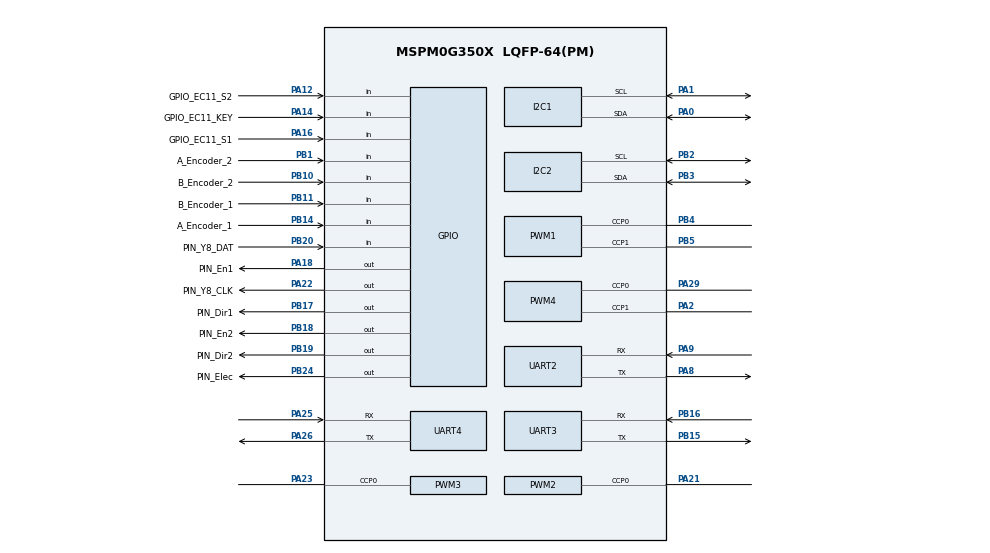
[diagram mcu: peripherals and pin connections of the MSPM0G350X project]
/**
 * @cliArgs --device "MSPM0G350X" --part "Default" --package "LQFP-64(PM)" --product "mspm0_sdk@2.09.00.00"
 * @versions {"tool":"1.26.0+4407"}
 */

/**
 * Import the modules used in this configuration.
 */
const GPIO   = scripting.addModule("/ti/driverlib/GPIO", {}, false);
const GPIO1  = GPIO.addInstance();
const GPIO2  = GPIO.addInstance();
const GPIO3  = GPIO.addInstance();
const GPIO4  = GPIO.addInstance();
const GPIO5  = GPIO.addInstance();
const GPIO6  = GPIO.addInstance();
const GPIO7  = GPIO.addInstance();
const GPIO8  = GPIO.addInstance();
const GPIO9  = GPIO.addInstance();
const GPIO10 = GPIO.addInstance();
const GPIO11 = GPIO.addInstance();
const GPIO12 = GPIO.addInstance();
const GPIO13 = GPIO.addInstance();
const GPIO14 = GPIO.addInstance();
const I2C    = scripting.addModule("/ti/driverlib/I2C", {}, false);
const I2C1   = I2C.addInstance();
const I2C2   = I2C.addInstance();
const PWM    = scripting.addModule("/ti/driverlib/PWM", {}, false);
const PWM1   = PWM.addInstance();
const PWM2   = PWM.addInstance();
const PWM3   = PWM.addInstance();
const PWM4   = PWM.addInstance();
const SYSCTL = scripting.addModule("/ti/driverlib/SYSCTL");
const TIMER  = scripting.addModule("/ti/driverlib/TIMER", {}, false);
const TIMER1 = TIMER.addInstance();
const TIMER2 = TIMER.addInstance();
const TIMER3 = TIMER.addInstance();
const UART   = scripting.addModule("/ti/driverlib/UART", {}, false);
const UART1  = UART.addInstance();
const UART2  = UART.addInstance();
const UART3  = UART.addInstance();
const UART4  = UART.addInstance();

/**
 * Write custom configuration values to the imported modules.
 */
GPIO1.$name                          = "GPIO_LED";
GPIO1.associatedPins.create(2);
GPIO1.associatedPins[0].$name        = "LED_PIN_0";
GPIO1.associatedPins[0].assignedPort = "PORTB";
GPIO1.associatedPins[0].assignedPin  = "22";
GPIO1.associatedPins[1].$name        = "LED_Time";
GPIO1.associatedPins[1].assignedPort = "PORTB";
GPIO1.associatedPins[1].assignedPin  = "9";

const Board = scripting.addModule("/ti/driverlib/Board", {}, false);

GPIO2.$name                              = "GPIO_KEY";
GPIO2.associatedPins.create(3);
GPIO2.associatedPins[0].direction        = "INPUT";
GPIO2.associatedPins[0].internalResistor = "PULL_UP";
GPIO2.associatedPins[0].assignedPort     = "PORTB";
GPIO2.associatedPins[0].assignedPin      = "21";
GPIO2.associatedPins[0].$name            = "KEY_0";
GPIO2.associatedPins[1].$name            = "KEY_1";
GPIO2.associatedPins[1].direction        = "INPUT";
GPIO2.associatedPins[1].assignedPort     = "PORTA";
GPIO2.associatedPins[1].assignedPin      = "15";
GPIO2.associatedPins[1].internalResistor = "PULL_UP";
GPIO2.associatedPins[2].$name            = "KEY_2";
GPIO2.associatedPins[2].assignedPort     = "PORTA";
GPIO2.associatedPins[2].assignedPin      = "17";
GPIO2.associatedPins[2].direction        = "INPUT";
GPIO2.associatedPins[2].internalResistor = "PULL_UP";

GPIO3.$name                          = "GPIO_OLED";
GPIO3.associatedPins.create(2);
GPIO3.associatedPins[0].$name        = "OLED_SCL";
GPIO3.associatedPins[0].initialValue = "SET";
GPIO3.associatedPins[0].assignedPort = "PORTA";
GPIO3.associatedPins[0].assignedPin  = "31";
GPIO3.associatedPins[1].$name        = "OLED_SDA";
GPIO3.associatedPins[1].initialValue = "SET";
GPIO3.associatedPins[1].assignedPort = "PORTA";
GPIO3.associatedPins[1].assignedPin  = "28";

GPIO4.$name                               = "GPIO_ENCODER_A";
GPIO4.associatedPins.create(2);
GPIO4.associatedPins[0].$name             = "A_Encoder_1";
GPIO4.associatedPins[0].direction         = "INPUT";
GPIO4.associatedPins[0].interruptEn       = true;
GPIO4.associatedPins[0].interruptPriority = "0";
GPIO4.associatedPins[0].polarity          = "RISE_FALL";
GPIO4.associatedPins[0].pin.$assign       = "PB14";
GPIO4.associatedPins[1].$name             = "A_Encoder_2";
GPIO4.associatedPins[1].direction         = "INPUT";
GPIO4.associatedPins[1].polarity          = "RISE_FALL";
GPIO4.associatedPins[1].pin.$assign       = "PB1";

GPIO5.$name                               = "GPIO_ENCODER_B";
GPIO5.associatedPins.create(2);
GPIO5.associatedPins[0].direction         = "INPUT";
GPIO5.associatedPins[0].interruptEn       = true;
GPIO5.associatedPins[0].polarity          = "RISE_FALL";
GPIO5.associatedPins[0].$name             = "B_Encoder_1";
GPIO5.associatedPins[0].interruptPriority = "0";
GPIO5.associatedPins[0].pin.$assign       = "PB11";
GPIO5.associatedPins[1].direction         = "INPUT";
GPIO5.associatedPins[1].polarity          = "RISE_FALL";
GPIO5.associatedPins[1].$name             = "B_Encoder_2";
GPIO5.associatedPins[1].pin.$assign       = "PB10";

GPIO6.$name                          = "GPIO_MOTOR_IN2";
GPIO6.associatedPins.create(2);
GPIO6.associatedPins[0].$name        = "AIN2";
GPIO6.associatedPins[0].assignedPort = "PORTB";
GPIO6.associatedPins[0].assignedPin  = "12";
GPIO6.associatedPins[1].$name        = "BIN2";
GPIO6.associatedPins[1].assignedPort = "PORTB";
GPIO6.associatedPins[1].assignedPin  = "13";

GPIO7.$name                          = "GPIO_RGB";
GPIO7.associatedPins.create(3);
GPIO7.associatedPins[0].$name        = "LED_R";
GPIO7.associatedPins[0].assignedPort = "PORTB";
GPIO7.associatedPins[0].assignedPin  = "6";
GPIO7.associatedPins[1].$name        = "LED_G";
GPIO7.associatedPins[1].assignedPort = "PORTB";
GPIO7.associatedPins[1].assignedPin  = "7";
GPIO7.associatedPins[2].$name        = "LED_B";
GPIO7.associatedPins[2].assignedPin  = "8";
GPIO7.associatedPins[2].assignedPort = "PORTB";

GPIO8.$name                              = "GPIO_TCRT";
GPIO8.associatedPins[0].$name            = "TCRT_0";
GPIO8.associatedPins[0].direction        = "INPUT";
GPIO8.associatedPins[0].internalResistor = "PULL_UP";
GPIO8.associatedPins[0].assignedPort     = "PORTA";
GPIO8.associatedPins[0].assignedPin      = "13";

GPIO9.$name                               = "GPIO_EC11";
GPIO9.associatedPins.create(3);
GPIO9.associatedPins[0].$name             = "GPIO_EC11_KEY";
GPIO9.associatedPins[0].direction         = "INPUT";
GPIO9.associatedPins[0].internalResistor  = "PULL_UP";
GPIO9.associatedPins[0].pin.$assign       = "PA14";
GPIO9.associatedPins[1].$name             = "GPIO_EC11_S1";
GPIO9.associatedPins[1].direction         = "INPUT";
GPIO9.associatedPins[1].internalResistor  = "PULL_UP";
GPIO9.associatedPins[1].interruptEn       = true;
GPIO9.associatedPins[1].polarity          = "FALL";
GPIO9.associatedPins[1].interruptPriority = "2";
GPIO9.associatedPins[1].pin.$assign       = "PA16";
GPIO9.associatedPins[2].$name             = "GPIO_EC11_S2";
GPIO9.associatedPins[2].direction         = "INPUT";
GPIO9.associatedPins[2].interruptEn       = true;
GPIO9.associatedPins[2].internalResistor  = "PULL_UP";
GPIO9.associatedPins[2].polarity          = "FALL";
GPIO9.associatedPins[2].interruptPriority = "2";
GPIO9.associatedPins[2].pin.$assign       = "PA12";

GPIO10.$name                         = "GPIO_Stepper1";
GPIO10.associatedPins.create(2);
GPIO10.associatedPins[0].$name       = "PIN_En1";
GPIO10.associatedPins[0].pin.$assign = "PA18";
GPIO10.associatedPins[1].$name       = "PIN_Dir1";
GPIO10.associatedPins[1].pin.$assign = "PB17";

GPIO11.$name                         = "GPIO_Stepper2";
GPIO11.associatedPins.create(2);
GPIO11.associatedPins[0].$name       = "PIN_En2";
GPIO11.associatedPins[0].pin.$assign = "PB18";
GPIO11.associatedPins[1].$name       = "PIN_Dir2";
GPIO11.associatedPins[1].pin.$assign = "PB19";

GPIO12.$name                              = "GPIO_Y8";
GPIO12.associatedPins.create(2);
GPIO12.associatedPins[0].$name            = "PIN_Y8_CLK";
GPIO12.associatedPins[0].pin.$assign      = "PA22";
GPIO12.associatedPins[1].$name            = "PIN_Y8_DAT";
GPIO12.associatedPins[1].direction        = "INPUT";
GPIO12.associatedPins[1].internalResistor = "PULL_UP";
GPIO12.associatedPins[1].pin.$assign      = "PB20";

GPIO13.$name                   = "GPIO_Buzzer";
GPIO13.associatedPins[0].$name = "PIN_Buzzer";

GPIO14.$name                         = "GPIO_Elec";
GPIO14.associatedPins[0].$name       = "PIN_Elec";
GPIO14.associatedPins[0].pin.$assign = "PB24";

I2C1.$name                           = "I2C_0";
I2C1.basicEnableController           = true;
I2C1.basicControllerStandardBusSpeed = "Fast";
I2C1.peripheral.$assign              = "I2C0";
I2C1.peripheral.sdaPin.$assign       = "PA0";
I2C1.peripheral.sclPin.$assign       = "PA1";
I2C1.sdaPinConfig.$name              = "ti_driverlib_gpio_GPIOPinGeneric8";
I2C1.sclPinConfig.$name              = "ti_driverlib_gpio_GPIOPinGeneric9";

I2C2.$name                           = "I2C_1";
I2C2.basicEnableController           = true;
I2C2.basicControllerStandardBusSpeed = "Fast";
I2C2.peripheral.$assign              = "I2C1";
I2C2.peripheral.sdaPin.$assign       = "PB3";
I2C2.peripheral.sclPin.$assign       = "PB2";
I2C2.sdaPinConfig.$name              = "ti_driverlib_gpio_GPIOPinGeneric10";
I2C2.sdaPinConfig.enableConfig       = true;
I2C2.sdaPinConfig.internalResistor   = "PULL_UP";
I2C2.sclPinConfig.$name              = "ti_driverlib_gpio_GPIOPinGeneric11";
I2C2.sclPinConfig.enableConfig       = true;
I2C2.sclPinConfig.internalResistor   = "PULL_UP";

PWM1.clockDivider                       = 8;
PWM1.timerStartTimer                    = true;
PWM1.pwmMode                            = "EDGE_ALIGN_UP";
PWM1.$name                              = "PWM_MOTOR_PWM";
PWM1.peripheral.$assign                 = "TIMA1";
PWM1.peripheral.ccp0Pin.$assign         = "PB4";
PWM1.peripheral.ccp1Pin.$assign         = "PB5";
PWM1.PWM_CHANNEL_0.$name                = "ti_driverlib_pwm_PWMTimerCC0";
PWM1.PWM_CHANNEL_1.$name                = "ti_driverlib_pwm_PWMTimerCC1";
PWM1.ccp0PinConfig.direction            = scripting.forceWrite("OUTPUT");
PWM1.ccp0PinConfig.hideOutputInversion  = scripting.forceWrite(false);
PWM1.ccp0PinConfig.onlyInternalResistor = scripting.forceWrite(false);
PWM1.ccp0PinConfig.passedPeripheralType = scripting.forceWrite("Digital");
PWM1.ccp0PinConfig.$name                = "ti_driverlib_gpio_GPIOPinGeneric0";
PWM1.ccp1PinConfig.$name                = "ti_driverlib_gpio_GPIOPinGeneric5";
PWM1.ccp1PinConfig.direction            = scripting.forceWrite("OUTPUT");
PWM1.ccp1PinConfig.hideOutputInversion  = scripting.forceWrite(false);
PWM1.ccp1PinConfig.onlyInternalResistor = scripting.forceWrite(false);
PWM1.ccp1PinConfig.passedPeripheralType = scripting.forceWrite("Digital");

PWM2.$name                              = "PWM_Stepper1";
PWM2.timerStartTimer                    = true;
PWM2.pwmMode                            = "EDGE_ALIGN_UP";
PWM2.ccIndex                            = [0];
PWM2.clockDivider                       = 8;
PWM2.PWM_CHANNEL_0.$name                = "ti_driverlib_pwm_PWMTimerCC2";
PWM2.ccp0PinConfig.direction            = scripting.forceWrite("OUTPUT");
PWM2.ccp0PinConfig.hideOutputInversion  = scripting.forceWrite(false);
PWM2.ccp0PinConfig.onlyInternalResistor = scripting.forceWrite(false);
PWM2.ccp0PinConfig.passedPeripheralType = scripting.forceWrite("Digital");
PWM2.ccp0PinConfig.$name                = "ti_driverlib_gpio_GPIOPinGeneric12";
PWM2.peripheral.$assign                 = "TIMG6";
PWM2.peripheral.ccp0Pin.$assign         = "PA21";

PWM3.$name                              = "PWM_Stepper2";
PWM3.timerStartTimer                    = true;
PWM3.pwmMode                            = "EDGE_ALIGN_UP";
PWM3.ccIndex                            = [0];
PWM3.clockDivider                       = 8;
PWM3.PWM_CHANNEL_0.$name                = "ti_driverlib_pwm_PWMTimerCC3";
PWM3.ccp0PinConfig.direction            = scripting.forceWrite("OUTPUT");
PWM3.ccp0PinConfig.hideOutputInversion  = scripting.forceWrite(false);
PWM3.ccp0PinConfig.onlyInternalResistor = scripting.forceWrite(false);
PWM3.ccp0PinConfig.passedPeripheralType = scripting.forceWrite("Digital");
PWM3.ccp0PinConfig.$name                = "ti_driverlib_gpio_GPIOPinGeneric13";
PWM3.peripheral.$assign                 = "TIMG7";
PWM3.peripheral.ccp0Pin.$assign         = "PA23";

PWM4.$name                              = "PWM_Servo";
PWM4.pwmMode                            = "EDGE_ALIGN_UP";
PWM4.timerCount                         = 20000;
PWM4.timerStartTimer                    = true;
PWM4.clockDivider                       = 8;
PWM4.clockPrescale                      = 4;
PWM4.peripheral.$assign                 = "TIMG8";
PWM4.peripheral.ccp0Pin.$assign         = "PA29";
PWM4.peripheral.ccp1Pin.$assign         = "PA2";
PWM4.PWM_CHANNEL_0.$name                = "ti_driverlib_pwm_PWMTimerCC4";
PWM4.PWM_CHANNEL_1.$name                = "ti_driverlib_pwm_PWMTimerCC5";
PWM4.ccp0PinConfig.direction            = scripting.forceWrite("OUTPUT");
PWM4.ccp0PinConfig.hideOutputInversion  = scripting.forceWrite(false);
PWM4.ccp0PinConfig.onlyInternalResistor = scripting.forceWrite(false);
PWM4.ccp0PinConfig.passedPeripheralType = scripting.forceWrite("Digital");
PWM4.ccp0PinConfig.$name                = "ti_driverlib_gpio_GPIOPinGeneric14";
PWM4.ccp1PinConfig.direction            = scripting.forceWrite("OUTPUT");
PWM4.ccp1PinConfig.hideOutputInversion  = scripting.forceWrite(false);
PWM4.ccp1PinConfig.onlyInternalResistor = scripting.forceWrite(false);
PWM4.ccp1PinConfig.passedPeripheralType = scripting.forceWrite("Digital");
PWM4.ccp1PinConfig.$name                = "ti_driverlib_gpio_GPIOPinGeneric15";

SYSCTL.forceDefaultClkConfig = true;

TIMER1.$name              = "TIMER_0";
TIMER1.interrupts         = ["ZERO"];
TIMER1.timerStartTimer    = true;
TIMER1.timerMode          = "PERIODIC";
TIMER1.timerPeriod        = "1 ms";
TIMER1.peripheral.$assign = "TIMG0";

TIMER2.$name            = "TIMER_1";
TIMER2.timerClkDiv      = 8;
TIMER2.timerClkPrescale = 100;
TIMER2.timerMode        = "PERIODIC";
TIMER2.timerPeriod      = "20 ms";
TIMER2.timerStartTimer  = true;
TIMER2.interrupts       = ["ZERO"];

TIMER3.$name              = "TIMER_2";
TIMER3.timerMode          = "PERIODIC";
TIMER3.timerClkDiv        = 8;
TIMER3.timerStartTimer    = true;
TIMER3.timerPeriod        = "1 ms";
TIMER3.peripheral.$assign = "TIMG12";

UART1.$name              = "UART_0";
UART1.targetBaudRate     = 115200;
UART1.rxFifoThreshold    = "DL_UART_RX_FIFO_LEVEL_ONE_ENTRY";
UART1.txFifoThreshold    = "DL_UART_TX_FIFO_LEVEL_ONE_ENTRY";
UART1.enabledInterrupts  = ["RX"];
UART1.peripheral.$assign = "UART0";
UART1.txPinConfig.$name  = "ti_driverlib_gpio_GPIOPinGeneric1";
UART1.rxPinConfig.$name  = "ti_driverlib_gpio_GPIOPinGeneric2";

UART2.$name                        = "UART_1";
UART2.enabledInterrupts            = ["RX"];
UART2.targetBaudRate               = 115200;
UART2.peripheral.$assign           = "UART1";
UART2.peripheral.rxPin.$assign     = "PA9";
UART2.peripheral.txPin.$assign     = "PA8";
UART2.txPinConfig.$name            = "ti_driverlib_gpio_GPIOPinGeneric3";
UART2.rxPinConfig.$name            = "ti_driverlib_gpio_GPIOPinGeneric4";
UART2.rxPinConfig.enableConfig     = true;
UART2.rxPinConfig.internalResistor = "PULL_UP";

UART3.$name                    = "UART_2";
UART3.targetBaudRate           = 115200;
UART3.enabledInterrupts        = ["RX"];
UART3.peripheral.$assign       = "UART2";
UART3.peripheral.rxPin.$assign = "PB16";
UART3.peripheral.txPin.$assign = "PB15";
UART3.txPinConfig.$name        = "ti_driverlib_gpio_GPIOPinGeneric6";
UART3.rxPinConfig.$name        = "ti_driverlib_gpio_GPIOPinGeneric7";

UART4.$name                    = "UART_3";
UART4.targetBaudRate           = 115200;
UART4.enabledInterrupts        = ["RX"];
UART4.peripheral.rxPin.$assign = "PA25";
UART4.peripheral.txPin.$assign = "PA26";
UART4.txPinConfig.$name        = "ti_driverlib_gpio_GPIOPinGeneric16";
UART4.rxPinConfig.$name        = "ti_driverlib_gpio_GPIOPinGeneric17";

/**
 * Pinmux solution for unlocked pins/peripherals. This ensures that minor changes to the automatic solver in a future
 * version of the tool will not impact the pinmux you originally saw.  These lines can be completely deleted in order to
 * re-solve from scratch.
 */
GPIO1.associatedPins[0].pin.$suggestSolution  = "PB22";
GPIO1.associatedPins[1].pin.$suggestSolution  = "PB9";
Board.peripheral.$suggestSolution             = "DEBUGSS";
Board.peripheral.swclkPin.$suggestSolution    = "PA20";
Board.peripheral.swdioPin.$suggestSolution    = "PA19";
GPIO2.associatedPins[0].pin.$suggestSolution  = "PB21";
GPIO2.associatedPins[1].pin.$suggestSolution  = "PA15";
GPIO2.associatedPins[2].pin.$suggestSolution  = "PA17";
GPIO3.associatedPins[0].pin.$suggestSolution  = "PA31";
GPIO3.associatedPins[1].pin.$suggestSolution  = "PA28";
GPIO6.associatedPins[0].pin.$suggestSolution  = "PB12";
GPIO6.associatedPins[1].pin.$suggestSolution  = "PB13";
GPIO7.associatedPins[0].pin.$suggestSolution  = "PB6";
GPIO7.associatedPins[1].pin.$suggestSolution  = "PB7";
GPIO7.associatedPins[2].pin.$suggestSolution  = "PB8";
GPIO8.associatedPins[0].pin.$suggestSolution  = "PA13";
GPIO13.associatedPins[0].pin.$suggestSolution = "PB23";
SYSCTL.peripheral.$suggestSolution            = "SYSCTL";
TIMER2.peripheral.$suggestSolution            = "TIMA0";
UART1.peripheral.rxPin.$suggestSolution       = "PA11";
UART1.peripheral.txPin.$suggestSolution       = "PA10";
UART4.peripheral.$suggestSolution             = "UART3";
